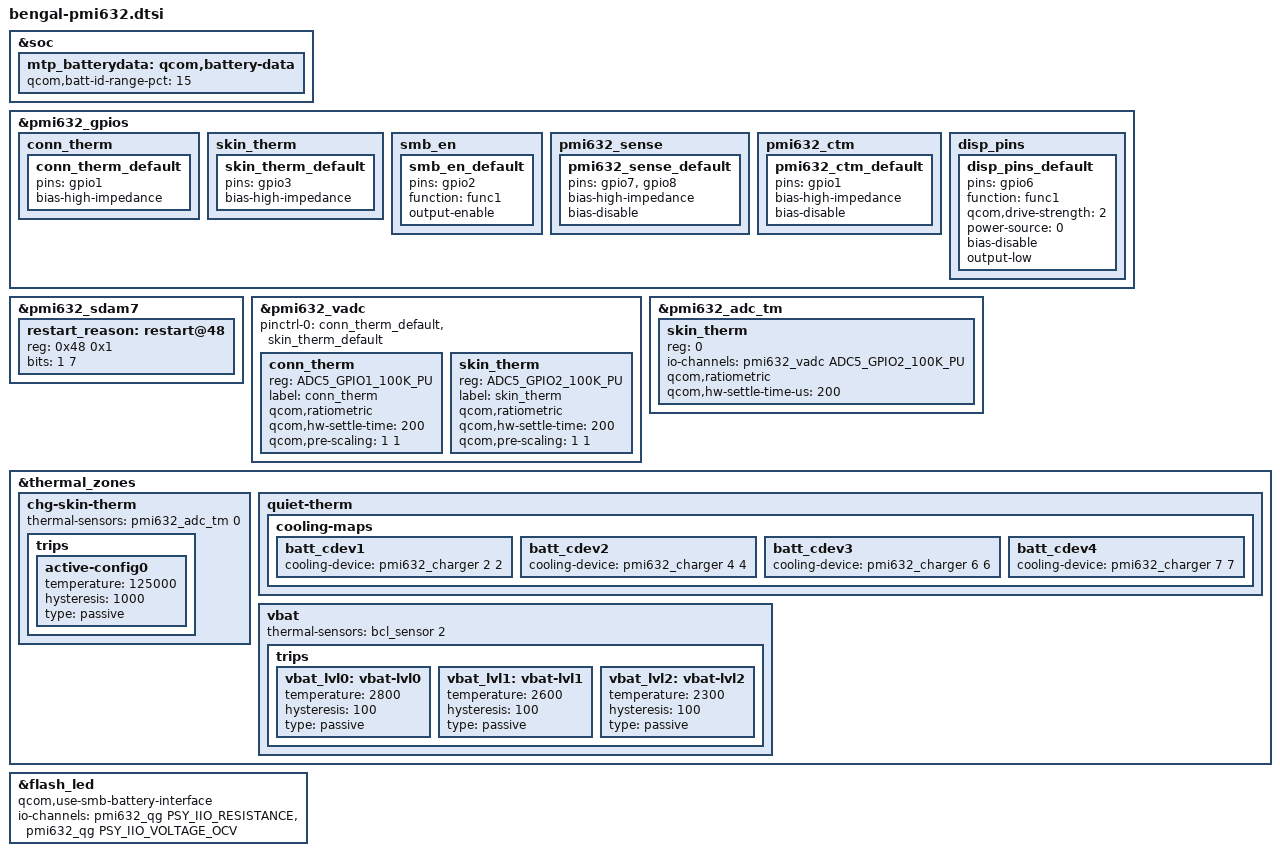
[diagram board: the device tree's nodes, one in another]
// SPDX-License-Identifier: BSD-3-Clause
/*
 * Copyright (c) Qualcomm Technologies, Inc. and/or its subsidiaries.
 */

#include "pmi632.dtsi"
#include <dt-bindings/iio/qti_power_supply_iio.h>

&soc {
	mtp_batterydata: qcom,battery-data {
		qcom,batt-id-range-pct = <15>;
		#include "qg-batterydata-alium-3600mah.dtsi"
	};
};

&pmi632_gpios {
	conn_therm {
		conn_therm_default: conn_therm_default {
			pins = "gpio1";
			bias-high-impedance;
		};
	};

	skin_therm {
		skin_therm_default: skin_therm_default {
			pins = "gpio3";
			bias-high-impedance;
		};
	};
};

&pmi632_sdam7 {
	#address-cells = <1>;
	#size-cells = <1>;

	restart_reason: restart@48 {
		reg = <0x48 0x1>;
		bits = <1 7>;
	};
};

&pmi632_vadc {
	#address-cells = <1>;
	#size-cells = <0>;
	pinctrl-names = "default";
	pinctrl-0 = <&conn_therm_default &skin_therm_default>;

	conn_therm {
		reg = <ADC5_GPIO1_100K_PU>;
		label = "conn_therm";
		qcom,ratiometric;
		qcom,hw-settle-time = <200>;
		qcom,pre-scaling = <1 1>;
	};

	skin_therm {
		reg = <ADC5_GPIO2_100K_PU>;
		label = "skin_therm";
		qcom,ratiometric;
		qcom,hw-settle-time = <200>;
		qcom,pre-scaling = <1 1>;
	};
};

&pmi632_adc_tm {
	/* Channel nodes */
	skin_therm {
		reg = <0>;
		io-channels = <&pmi632_vadc ADC5_GPIO2_100K_PU>;
		qcom,ratiometric;
		qcom,hw-settle-time-us = <200>;
	};
};

&pmi632_gpios {
	smb_en {
		smb_en_default: smb_en_default {
			pins = "gpio2";
			function = "func1";
			output-enable;
		 };
	};

	pmi632_sense {
		/* GPIO 7 and 8 are external-sense pins for PMI632 */
		pmi632_sense_default: pmi632_sense_default {
			pins = "gpio7", "gpio8";
			bias-high-impedance;    /* disable the GPIO */
			bias-disable;           /* no-pull */
		};
	};

	pmi632_ctm {
		/* Disable GPIO1 for h/w base mitigation */
		pmi632_ctm_default: pmi632_ctm_default {
			pins = "gpio1";
			bias-high-impedance;    /* disable the GPIO */
			bias-disable;           /* no-pull */
		};
	};
};

&pmi632_gpios {
	disp_pins {
		disp_pins_default: disp_pins_default {
			pins = "gpio6";
			function = "func1";
			qcom,drive-strength = <2>;
			power-source = <0>;
			bias-disable;
			output-low;
		};
	};
};

&thermal_zones {
	chg-skin-therm {
		thermal-sensors = <&pmi632_adc_tm 0>;
		trips {
			active-config0 {
				temperature = <125000>;
				hysteresis = <1000>;
				type = "passive";
			};
		};
	};

	quiet-therm {
		cooling-maps {
			batt_cdev1 {
				cooling-device = <&pmi632_charger 2 2>;
			};

			batt_cdev2 {
				cooling-device = <&pmi632_charger 4 4>;
			};

			batt_cdev3 {
				cooling-device = <&pmi632_charger 6 6>;
			};

			batt_cdev4 {
				cooling-device = <&pmi632_charger 7 7>;
			};
		};
	};

	vbat {
		thermal-sensors = <&bcl_sensor 2>;
		trips {
			vbat_lvl0:vbat-lvl0 {
				temperature = <2800>;
				hysteresis = <100>;
				type = "passive";
			};

			vbat_lvl1:vbat-lvl1 {
				temperature = <2600>;
				hysteresis = <100>;
				type = "passive";
			};

			vbat_lvl2:vbat-lvl2 {
				temperature = <2300>;
				hysteresis = <100>;
				type = "passive";
			};
		};
	};
};

&flash_led {
	qcom,use-smb-battery-interface;
	io-channels =  <&pmi632_qg PSY_IIO_RESISTANCE>,
		       <&pmi632_qg PSY_IIO_VOLTAGE_OCV>;
	io-channel-names = "rbatt",
			   "voltage_ocv";
};
